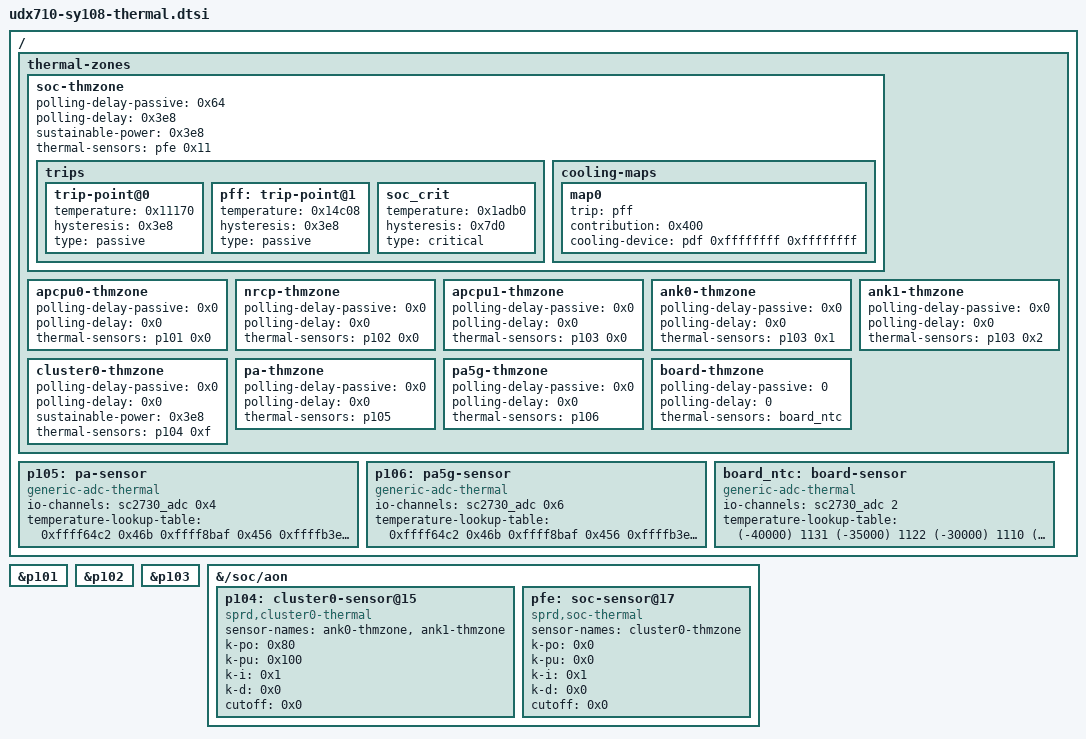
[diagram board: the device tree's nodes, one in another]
// SPDX-License-Identifier: GPL-2.0-only
/* 4H10 sensor selection, NTC wiring/curves, aggregation and cooling policy. */
&p101 { status = "okay"; };
&p102 { status = "okay"; };
&p103 { status = "okay"; };

&{/soc/aon} {
	p104: cluster0-sensor@15 {
		compatible = "sprd,cluster0-thermal";
		#thermal-sensor-cells = <0x1>;
		sensor-names = "ank0-thmzone", "ank1-thmzone";
		k-po = <0x80>;
		k-pu = <0x100>;
		k-i = <0x1>;
		k-d = <0x0>;
		cutoff = <0x0>;
		phandle = <0x104>;
		status = "okay";
	};

	pfe: soc-sensor@17 {
		compatible = "sprd,soc-thermal";
		#thermal-sensor-cells = <0x1>;
		sensor-names = "cluster0-thmzone";
		k-po = <0x0>;
		k-pu = <0x0>;
		k-i = <0x1>;
		k-d = <0x0>;
		cutoff = <0x0>;
		phandle = <0xfe>;
		status = "okay";
	};
};

/ {
	thermal-zones {
		soc-thmzone {
			polling-delay-passive = <0x64>;
			polling-delay = <0x3e8>;
			sustainable-power = <0x3e8>;
			thermal-sensors = <&pfe 0x11>;
			status = "okay";
			trips {
				trip-point@0 {
					temperature = <0x11170>;
					hysteresis = <0x3e8>;
					type = "passive";
				};
				pff: trip-point@1 {
					temperature = <0x14c08>;
					hysteresis = <0x3e8>;
					type = "passive";
					phandle = <0xff>;
				};
				soc_crit {
					temperature = <0x1adb0>;
					hysteresis = <0x7d0>;
					type = "critical";
				};
			};
			cooling-maps {
				map0 {
					trip = <&pff>;
					contribution = <0x400>;
					cooling-device = <&pdf 0xffffffff 0xffffffff>;
				};
			};
		};
		apcpu0-thmzone {
			polling-delay-passive = <0x0>;
			polling-delay = <0x0>;
			thermal-sensors = <&p101 0x0>;
		};
		nrcp-thmzone {
			polling-delay-passive = <0x0>;
			polling-delay = <0x0>;
			thermal-sensors = <&p102 0x0>;
		};
		apcpu1-thmzone {
			polling-delay-passive = <0x0>;
			polling-delay = <0x0>;
			thermal-sensors = <&p103 0x0>;
		};
		ank0-thmzone {
			polling-delay-passive = <0x0>;
			polling-delay = <0x0>;
			thermal-sensors = <&p103 0x1>;
		};
		ank1-thmzone {
			polling-delay-passive = <0x0>;
			polling-delay = <0x0>;
			thermal-sensors = <&p103 0x2>;
		};
		cluster0-thmzone {
			polling-delay-passive = <0x0>;
			polling-delay = <0x0>;
			sustainable-power = <0x3e8>;
			thermal-sensors = <&p104 0xf>;
			status = "okay";
		};
		pa-thmzone {
			polling-delay-passive = <0x0>;
			polling-delay = <0x0>;
			thermal-sensors = <&p105>;
			status = "okay";
		};
		pa5g-thmzone {
			polling-delay-passive = <0x0>;
			polling-delay = <0x0>;
			thermal-sensors = <&p106>;
			status = "okay";
		};
		board-thmzone {
			polling-delay-passive = <0>;
			polling-delay = <0>;
			thermal-sensors = <&board_ntc>;
		};
	};
	p105: pa-sensor {
		compatible = "generic-adc-thermal";
		#thermal-sensor-cells = <0x0>;
		io-channels = <&sc2730_adc 0x4>;
		io-channel-names = "sensor-channel";
		temperature-lookup-table = <0xffff64c2 0x46b 0xffff8baf 0x456 0xffffb3e8 0x432 0xffffedb9 0x3d7 0x277e 0x346 0x60e5 0x28e 0xaf7a 0x19d 0xd677 0x13c 0xfd7f 0xee 0x12484 0xb2 0x14b93 0x85 0x172a3 0x64 0x199b0 0x4b 0x1c0c9 0x39 0x1e7c8 0x2b>;
		phandle = <0x105>;
		status = "okay";
	};
	p106: pa5g-sensor {
		compatible = "generic-adc-thermal";
		#thermal-sensor-cells = <0x0>;
		io-channels = <&sc2730_adc 0x6>;
		io-channel-names = "sensor-channel";
		temperature-lookup-table = <0xffff64c2 0x46b 0xffff8baf 0x456 0xffffb3e8 0x432 0xffffedb9 0x3d7 0x277e 0x346 0x60e5 0x28e 0xaf7a 0x19d 0xd677 0x13c 0xfd7f 0xee 0x12484 0xb2 0x14b93 0x85 0x172a3 0x64 0x199b0 0x4b 0x1c0c9 0x39 0x1e7c8 0x2b>;
		phandle = <0x106>;
		status = "okay";
	};
	board_ntc: board-sensor {
	 compatible = "generic-adc-thermal";
	 #thermal-sensor-cells = <0>;
	 io-channels = <&sc2730_adc 2>;
	 io-channel-names = "sensor-channel";
	 /* 4H10 stock47k NTC table, V=180000*R/(5600000+156*R), in mV. */
	 temperature-lookup-table = <(-40000) 1131
	  (-35000) 1122
	  (-30000) 1110
	  (-25000) 1094
	  (-20000) 1074
	  (-15000) 1049
	  (-10000) 1019
	  (-5000) 983
	  (0) 940
	  (5000) 892
	  (10000) 838
	  (15000) 779
	  (20000) 718
	  (25000) 654
	  (30000) 591
	  (35000) 528
	  (40000) 469
	  (45000) 413
	  (50000) 362
	  (55000) 316
	  (60000) 275
	  (65000) 238
	  (70000) 206
	  (75000) 178
	  (80000) 154
	  (85000) 133
	  (90000) 115
	  (95000) 100
	  (100000) 86
	  (105000) 75
	  (110000) 65
	  (115000) 57
	  (120000) 50
	  (125000) 43>;
	};
};
